# f28004x_sci_regs register map
Vendor: Texas Instruments
Peripheral module from a debugger description file (folder C2000).
Address unit: 16 bits
Registers are 16-bit, read-write, no defined reset value unless marked. A register's access mark holds for its fields unless they carry their own. Offsets are as the file gives them; lines under a group give offsets from that group; [hi:lo] are bit positions; {n}, {i} and the like mark numbered series; 'fields as' and 'values as' point back to an identical list; <NAME> marks a mode.

## SCI_REGS — SCI Registers
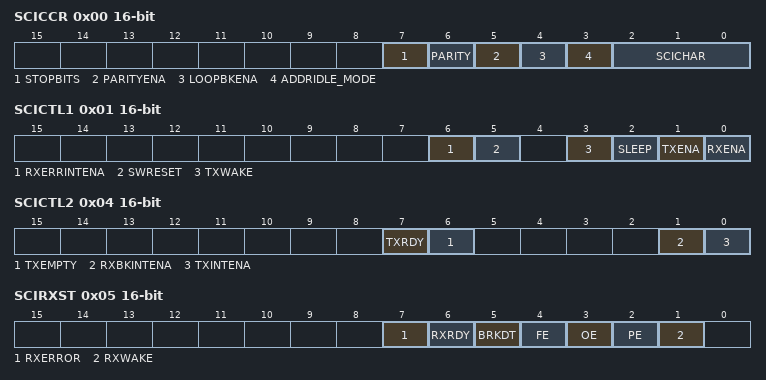
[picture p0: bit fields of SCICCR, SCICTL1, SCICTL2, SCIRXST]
0x00 SCICCR — Communications control register
  [7] STOPBITS — Number of Stop Bits
  [6] PARITY — Even or Odd Parity
  [5] PARITYENA — Parity enable
  [4] LOOPBKENA — Loop Back enable
  [3] ADDRIDLE_MODE — ADDR/IDLE Mode control
  [2:0] SCICHAR — Character length control
0x01 SCICTL1 — Control register 1
  [6] RXERRINTENA — Receive __interrupt enable
  [5] SWRESET — Software reset
  [3] TXWAKE — Transmitter wakeup method
  [2] SLEEP — SCI sleep
  [1] TXENA — SCI transmitter enable
  [0] RXENA — SCI receiver enable
0x02 SCIHBAUD — Baud rate (high) register
  [7:0] BAUD — SCI 16-bit baud selection Registers SCIHBAUD
0x03 SCILBAUD — Baud rate (low) register
  [7:0] BAUD — SCI 16-bit baud selection Registers SCILBAUD
0x04 SCICTL2 access per field — Control register 2
  [7] TXRDY ro — Transmitter ready flag
  [6] TXEMPTY ro — Transmitter empty flag
  [1] RXBKINTENA rw — Receiver-buffer break enable
  [0] TXINTENA rw — Transmit __interrupt enable
0x05 SCIRXST ro — Receive status register
  [7] RXERROR — Receiver error flag
  [6] RXRDY — Receiver ready flag
  [5] BRKDT — Break-detect flag
  [4] FE — Framing error flag
  [3] OE — Overrun error flag
  [2] PE — Parity error flag
  [1] RXWAKE — Receiver wakeup detect flag
0x06 SCIRXEMU ro — Receive emulation buffer register
  [7:0] ERXDT — Receive emulation buffer data
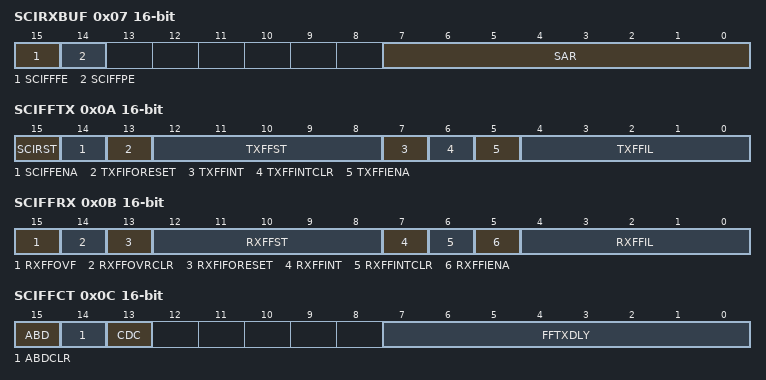
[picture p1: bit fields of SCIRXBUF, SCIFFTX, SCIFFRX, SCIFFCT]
0x07 SCIRXBUF ro — Receive data buffer
  [15] SCIFFFE — Receiver error flag
  [14] SCIFFPE — Receiver error flag
  [7:0] SAR — Receive Character bits
0x09 SCITXBUF — Transmit data buffer
  [7:0] TXDT
0x0A SCIFFTX access not given — FIFO transmit register
  [15] SCIRST rw — SCI reset rx/tx channels
  [14] SCIFFENA rw — Enhancement enable
  [13] TXFIFORESET rw — FIFO reset
  [12:8] TXFFST ro — FIFO status
  [7] TXFFINT ro — INT flag
  [6] TXFFINTCLR — Clear INT flag (access R=0/W=1)
  [5] TXFFIENA rw — Interrupt enable
  [4:0] TXFFIL rw — Interrupt level
0x0B SCIFFRX access not given — FIFO Receive register
  [15] RXFFOVF ro — FIFO overflow
  [14] RXFFOVRCLR — Clear overflow (access R=0/W=1)
  [13] RXFIFORESET rw — FIFO reset
  [12:8] RXFFST ro — FIFO status
  [7] RXFFINT ro — INT flag
  [6] RXFFINTCLR wo — Clear INT flag
  [5] RXFFIENA rw — Interrupt enable
  [4:0] RXFFIL rw — Interrupt level
0x0C SCIFFCT access per field — FIFO control register
  [15] ABD ro — Auto baud detect
  [14] ABDCLR wo — Auto baud clear
  [13] CDC rw — Auto baud mode enable
  [7:0] FFTXDLY rw — FIFO transmit delay
0x0F SCIPRI — SCI Priority control
  [4:3] FREESOFT — Emulation modes
